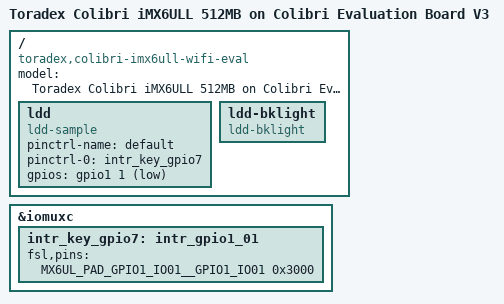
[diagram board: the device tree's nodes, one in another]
// SPDX-License-Identifier: GPL-2.0-or-later OR MIT
/*
 * Copyright 2018-2022 Toradex
 */

/dts-v1/;

#include "imx6ull-colibri-wifi.dtsi"
#include "imx6ull-colibri-eval-v3.dtsi"

/ {
	model = "Toradex Colibri iMX6ULL 512MB on Colibri Evaluation Board V3";
	compatible = "toradex,colibri-imx6ull-wifi-eval", "fsl,imx6ull";
       
        ldd{ 
             compatible = "ldd-sample";                             /* sample ldd node */
             pinctrl-name = "default";
             pinctrl-0 = <&intr_key_gpio7>;
             gpios = <&gpio1 1 GPIO_ACTIVE_LOW>;
             };
        ldd-bklight {
             compatible = "ldd-bklight";                           /*ldd backlight node */
             };

};

&iomuxc {
intr_key_gpio7: intr_gpio1_01 {                                       /*pin control for interrupt*/
		fsl,pins = <
			MX6UL_PAD_GPIO1_IO01__GPIO1_IO01        0x3000 /* SODIMM 6 */		
                 >;
	};

};
